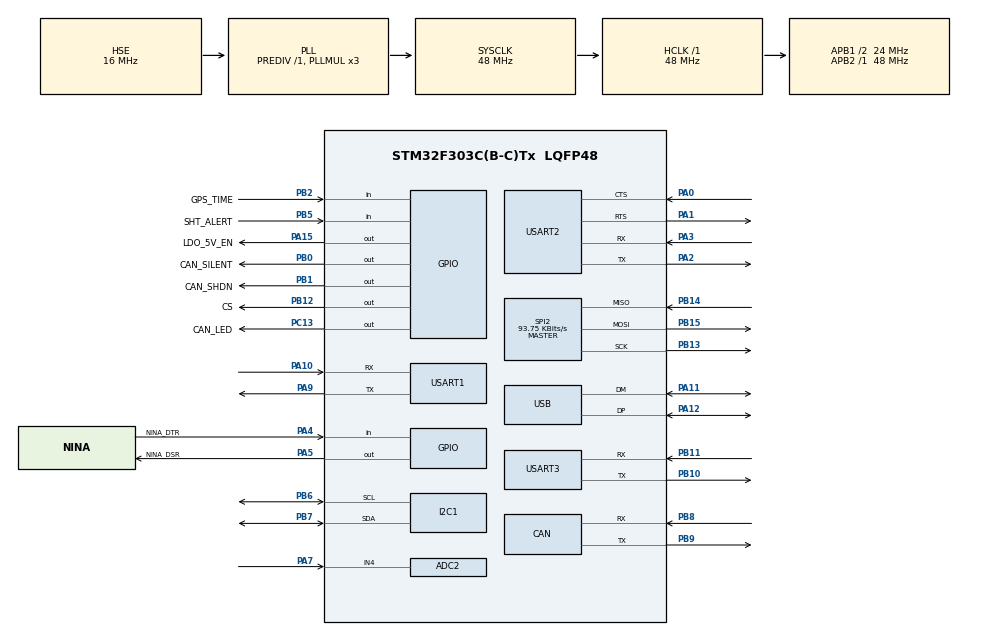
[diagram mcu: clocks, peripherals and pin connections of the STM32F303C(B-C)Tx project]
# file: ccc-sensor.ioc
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ADC2.Channel-0\#ChannelRegularConversion=ADC_CHANNEL_4
ADC2.NbrOfConversionFlag=1
ADC2.Offset-0\#ChannelRegularConversion=0
ADC2.OffsetNumber-0\#ChannelRegularConversion=ADC_OFFSET_NONE
ADC2.Rank-0\#ChannelRegularConversion=1
ADC2.SamplingTime-0\#ChannelRegularConversion=ADC_SAMPLETIME_1CYCLE_5
CAN.BS1=CAN_BS1_1TQ
CAN.BS2=CAN_BS2_1TQ
CAN.CalculateTimeQuantum=666.6666666666666
FREERTOS.INCLUDE_uxTaskGetStackHighWaterMark=1
FREERTOS.Tasks01=defaultTask,0,128,StartDefaultTask,Default,NULL
FREERTOS.configCHECK_FOR_STACK_OVERFLOW=1
FREERTOS.configUSE_TICKLESS_IDLE=1
Mcu.Family=STM32F3
Mcu.Name=STM32F303C(B-C)Tx
Mcu.Package=LQFP48
NVIC.PriorityGroup=NVIC_PRIORITYGROUP_4
NVIC.TIM1_UP_TIM16_IRQn=true\:0\:0\:false\:false\:true\:false\:false\:true
NVIC.TimeBase=TIM1_UP_TIM16_IRQn
NVIC.TimeBaseIP=TIM1
PA0.Mode=CTS_RTS
PA0.Signal=USART2_CTS
PA1.Mode=CTS_RTS
PA1.Signal=USART2_RTS
PA10.Mode=Asynchronous
PA10.Signal=USART1_RX
PA11.Mode=Device
PA11.Signal=USB_DM
PA12.Mode=Device
PA12.Signal=USB_DP
PA13.Mode=Serial_Wire
PA13.Signal=SYS_JTMS-SWDIO
PA14.Mode=Serial_Wire
PA14.Signal=SYS_JTCK-SWCLK
PA15.GPIO_Label=LDO_5V_EN
PA15.PinState=GPIO_PIN_SET
PA15.Signal=GPIO_Output
PA2.Mode=Asynchronous
PA2.Signal=USART2_TX
PA3.Mode=Asynchronous
PA3.Signal=USART2_RX
PA4.GPIO_Label=NINA_DTR
PA4.Signal=GPIO_Input
PA5.GPIO_Label=NINA_DSR
PA5.Signal=GPIO_Output
PA7.Mode=IN4-Single-Ended
PA7.Signal=ADC2_IN4
PA9.Mode=Asynchronous
PA9.Signal=USART1_TX
PB0.GPIO_Label=CAN_SILENT
PB0.Signal=GPIO_Output
PB1.GPIO_Label=CAN_SHDN
PB1.Signal=GPIO_Output
PB10.Mode=Asynchronous
PB10.Signal=USART3_TX
PB11.Mode=Asynchronous
PB11.Signal=USART3_RX
PB12.GPIO_Label=CS
PB12.Signal=GPIO_Output
PB13.Mode=Full_Duplex_Master
PB13.Signal=SPI2_SCK
PB14.Mode=Full_Duplex_Master
PB14.Signal=SPI2_MISO
PB15.Mode=Full_Duplex_Master
PB15.Signal=SPI2_MOSI
PB2.GPIO_Label=GPS_TIME
PB2.Signal=GPIO_Input
PB3.Signal=SYS_JTDO-TRACESWO
PB5.GPIO_Label=SHT_ALERT
PB5.Signal=GPIO_Input
PB6.Mode=I2C
PB6.Signal=I2C1_SCL
PB7.Mode=I2C
PB7.Signal=I2C1_SDA
PB8.Mode=Master
PB8.Signal=CAN_RX
PB9.Mode=Master
PB9.Signal=CAN_TX
PC13.GPIO_Label=CAN_LED
PC13.Signal=GPIO_Output
PC14-OSC32_IN.Mode=LSE-External-Oscillator
PC14-OSC32_IN.Signal=RCC_OSC32_IN
PC15-OSC32_OUT.Mode=LSE-External-Oscillator
PC15-OSC32_OUT.Signal=RCC_OSC32_OUT
PF0-OSC_IN.Mode=HSE-External-Oscillator
PF0-OSC_IN.Signal=RCC_OSC_IN
PF1-OSC_OUT.Mode=HSE-External-Oscillator
PF1-OSC_OUT.Signal=RCC_OSC_OUT
ProjectManager.HeapSize=0x200
ProjectManager.StackSize=0x400
ProjectManager.TargetToolchain=Makefile
RCC.AHBFreq_Value=48000000
RCC.APB1CLKDivider=RCC_HCLK_DIV2
RCC.APB1Freq_Value=24000000
RCC.APB1TimFreq_Value=48000000
RCC.APB2Freq_Value=48000000
RCC.APB2TimFreq_Value=48000000
RCC.CortexFreq_Value=48000000
RCC.HCLKFreq_Value=48000000
RCC.HSE_VALUE=16000000
RCC.HSI_VALUE=8000000
RCC.PLLMUL=RCC_PLL_MUL3
RCC.RTCClockSelection=RCC_RTCCLKSOURCE_LSE
RCC.SYSCLKFreq_VALUE=48000000
RCC.SYSCLKSourceVirtual=RCC_SYSCLKSOURCE_PLLCLK
RCC.USBFreq_Value=48000000
SPI2.BaudRatePrescaler=SPI_BAUDRATEPRESCALER_256
SPI2.CLKPhase=SPI_PHASE_2EDGE
SPI2.CalculateBaudRate=93.75 KBits/s
SPI2.DataSize=SPI_DATASIZE_8BIT
SPI2.Direction=SPI_DIRECTION_2LINES
SPI2.Mode=SPI_MODE_MASTER
SPI2.VirtualType=VM_MASTER
TIM6.Period=0xFFFF
TIM6.Prescaler=72-1
USART1.VirtualMode-Asynchronous=VM_ASYNC
USART2.VirtualMode-Asynchronous=VM_ASYNC
USART3.VirtualMode-Asynchronous=VM_ASYNC
VP_FREERTOS_VS_CMSIS_V1.Mode=CMSIS_V1
VP_RTC_VS_RTC_Activate.Mode=RTC_Enabled
VP_SYS_VS_tim1.Mode=TIM1
VP_TIM6_VS_ClockSourceINT.Mode=Enable_Timer
board=custom

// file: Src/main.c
/* USER CODE BEGIN Header */
/**
  ******************************************************************************
  * @file           : main.c
  * @brief          : Main program body
  ******************************************************************************
  * @attention
  *
  * <h2><center>&copy; Copyright (c) 2019 STMicroelectronics.
  * All rights reserved.</center></h2>
  *
  * This software component is licensed by ST under Ultimate Liberty license
  * SLA0044, the "License"; You may not use this file except in compliance with
  * the License. You may obtain a copy of the License at:
  *                             www.st.com/SLA0044
  *
  ******************************************************************************
  */
/* USER CODE END Header */

#include "main.h"
#include "cmsis_os.h"
#include "adc.h"
#include "can.h"
#include "i2c.h"
#include "rtc.h"
#include "spi.h"
#include "tim.h"
#include "usart.h"
#include "usb.h"
#include "gpio.h"

void SystemClock_Config(void);
void MX_FREERTOS_Init(void);

int main(void)
{

  /* MCU Configuration--------------------------------------------------------*/

  /* Reset of all peripherals, Initializes the Flash interface and the Systick. */
  HAL_Init();

  /* Configure the system clock */
  SystemClock_Config();

  /* Initialize all configured peripherals */
  MX_GPIO_Init();
  MX_CAN_Init();
  MX_SPI2_Init();
  MX_USART2_UART_Init();
  MX_ADC2_Init();
  MX_I2C1_Init();
  MX_RTC_Init();
  MX_TIM6_Init();
  MX_USART1_UART_Init();
  MX_USART3_UART_Init();
  MX_USB_PCD_Init();

  /* Call init function for freertos objects (in freertos.c) */
  MX_FREERTOS_Init();

  /* Start scheduler */
  osKernelStart();

  /* We should never get here as control is now taken by the scheduler */

  /* Infinite loop */
  while (1)
  {

  }
}

void SystemClock_Config(void)
{
  RCC_OscInitTypeDef RCC_OscInitStruct = {0};
  RCC_ClkInitTypeDef RCC_ClkInitStruct = {0};
  RCC_PeriphCLKInitTypeDef PeriphClkInit = {0};

  /** Configure LSE Drive Capability
  */
  HAL_PWR_EnableBkUpAccess();
  __HAL_RCC_LSEDRIVE_CONFIG(RCC_LSEDRIVE_LOW);
  /** Initializes the CPU, AHB and APB busses clocks
  */
  RCC_OscInitStruct.OscillatorType = RCC_OSCILLATORTYPE_HSI|RCC_OSCILLATORTYPE_HSE
                              |RCC_OSCILLATORTYPE_LSE;
  RCC_OscInitStruct.HSEState = RCC_HSE_ON;
  RCC_OscInitStruct.HSEPredivValue = RCC_HSE_PREDIV_DIV1;
  RCC_OscInitStruct.LSEState = RCC_LSE_ON;
  RCC_OscInitStruct.HSIState = RCC_HSI_ON;
  RCC_OscInitStruct.HSICalibrationValue = RCC_HSICALIBRATION_DEFAULT;
  RCC_OscInitStruct.PLL.PLLState = RCC_PLL_ON;
  RCC_OscInitStruct.PLL.PLLSource = RCC_PLLSOURCE_HSE;
  RCC_OscInitStruct.PLL.PLLMUL = RCC_PLL_MUL3;
  if (HAL_RCC_OscConfig(&RCC_OscInitStruct) != HAL_OK)
  {
    Error_Handler();
  }
  /** Initializes the CPU, AHB and APB busses clocks
  */
  RCC_ClkInitStruct.ClockType = RCC_CLOCKTYPE_HCLK|RCC_CLOCKTYPE_SYSCLK
                              |RCC_CLOCKTYPE_PCLK1|RCC_CLOCKTYPE_PCLK2;
  RCC_ClkInitStruct.SYSCLKSource = RCC_SYSCLKSOURCE_PLLCLK;
  RCC_ClkInitStruct.AHBCLKDivider = RCC_SYSCLK_DIV1;
  RCC_ClkInitStruct.APB1CLKDivider = RCC_HCLK_DIV2;
  RCC_ClkInitStruct.APB2CLKDivider = RCC_HCLK_DIV1;

  if (HAL_RCC_ClockConfig(&RCC_ClkInitStruct, FLASH_LATENCY_1) != HAL_OK)
  {
    Error_Handler();
  }
  PeriphClkInit.PeriphClockSelection = RCC_PERIPHCLK_USB|RCC_PERIPHCLK_USART1
                              |RCC_PERIPHCLK_USART2|RCC_PERIPHCLK_USART3
                              |RCC_PERIPHCLK_I2C1|RCC_PERIPHCLK_RTC
                              |RCC_PERIPHCLK_ADC12;
  PeriphClkInit.Usart1ClockSelection = RCC_USART1CLKSOURCE_PCLK2;
  PeriphClkInit.Usart2ClockSelection = RCC_USART2CLKSOURCE_PCLK1;
  PeriphClkInit.Usart3ClockSelection = RCC_USART3CLKSOURCE_PCLK1;
  PeriphClkInit.Adc12ClockSelection = RCC_ADC12PLLCLK_DIV1;
  PeriphClkInit.I2c1ClockSelection = RCC_I2C1CLKSOURCE_HSI;
  PeriphClkInit.RTCClockSelection = RCC_RTCCLKSOURCE_LSE;
  PeriphClkInit.USBClockSelection = RCC_USBCLKSOURCE_PLL;
  if (HAL_RCCEx_PeriphCLKConfig(&PeriphClkInit) != HAL_OK)
  {
    Error_Handler();
  }
}

void HAL_TIM_PeriodElapsedCallback(TIM_HandleTypeDef *htim)
{
  if (htim->Instance == TIM1) {
    HAL_IncTick();
  }
}

void Error_Handler(void)
{
}

/************************ (C) COPYRIGHT STMicroelectronics *****END OF FILE****/

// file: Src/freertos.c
/* USER CODE BEGIN Header */
/**
  ******************************************************************************
  * File Name          : freertos.c
  * Description        : Code for freertos applications
  ******************************************************************************
  * @attention
  *
  * <h2><center>&copy; Copyright (c) 2019 STMicroelectronics.
  * All rights reserved.</center></h2>
  *
  * This software component is licensed by ST under Ultimate Liberty license
  * SLA0044, the "License"; You may not use this file except in compliance with
  * the License. You may obtain a copy of the License at:
  *                             www.st.com/SLA0044
  *
  ******************************************************************************
  */
/* USER CODE END Header */

#include "FreeRTOS.h"
#include "task.h"
#include "main.h"
#include "cmsis_os.h"

osThreadId defaultTaskHandle;

void StartDefaultTask(void const * argument);

void MX_FREERTOS_Init(void); /* (MISRA C 2004 rule 8.1) */

/* Pre/Post sleep processing prototypes */
void PreSleepProcessing(uint32_t *ulExpectedIdleTime);
void PostSleepProcessing(uint32_t *ulExpectedIdleTime);

/* Hook prototypes */
void vApplicationStackOverflowHook(xTaskHandle xTask, signed char *pcTaskName);

/* USER CODE BEGIN 4 */
__weak void vApplicationStackOverflowHook(xTaskHandle xTask, signed char *pcTaskName)
{
   /* Run time stack overflow checking is performed if
   configCHECK_FOR_STACK_OVERFLOW is defined to 1 or 2. This hook function is
   called if a stack overflow is detected. */
}
/* USER CODE END 4 */

/* USER CODE BEGIN PREPOSTSLEEP */
__weak void PreSleepProcessing(uint32_t *ulExpectedIdleTime)
{
/* place for user code */
}

__weak void PostSleepProcessing(uint32_t *ulExpectedIdleTime)
{
/* place for user code */
}
/* USER CODE END PREPOSTSLEEP */

void MX_FREERTOS_Init(void) {

  /* Create the thread(s) */
  /* definition and creation of defaultTask */
  osThreadDef(defaultTask, StartDefaultTask, osPriorityNormal, 0, 128);
  defaultTaskHandle = osThreadCreate(osThread(defaultTask), NULL);

}

void StartDefaultTask(void const * argument)
{

  /* USER CODE BEGIN StartDefaultTask */
  /* Infinite loop */
  for(;;)
  {
    HAL_GPIO_TogglePin(CAN_LED_GPIO_Port,CAN_LED_Pin);
    osDelay(100);
  }
  /* USER CODE END StartDefaultTask */
}

/************************ (C) COPYRIGHT STMicroelectronics *****END OF FILE****/
